# MKE16F16 register map
Vendor: Freescale Semiconductor, Inc.; Series: Kinetis_E; File version: 1.6
CPU: CM4 r0p1, little endian, no MPU, FPU, VTOR, 4 interrupt priority bits
Registers are 32-bit, read-write, reset 0x0 unless marked. A register's access mark holds for its fields unless they carry their own. Offsets are from the block's base; [hi:lo] are bit positions; {n}, {i} and the like mark numbered series; 'fields as' and 'values as' point back to an identical list.

## MCM — Core Platform Miscellaneous Control Module
Base 0xE0080000; register names take the prefix MCM_
0x08 PLASC 16-bit ro reset 0x7 — Crossbar Switch (AXBS) Slave Configuration
  [7:0] ASC — Each bit in the ASC field indicates whether there is a corresponding connection to the crossbar switch's slave input port.
    0=A bus slave connection to AXBS input port n is absent; 1=A bus slave connection to AXBS input port n is present
0x0A PLAMC 16-bit ro reset 0x7 — Crossbar Switch (AXBS) Master Configuration
  [7:0] AMC — Each bit in the AMC field indicates whether there is a corresponding connection to the AXBS master input port.
    0=A bus master connection to AXBS input port n is absent; 1=A bus master connection to AXBS input port n is present
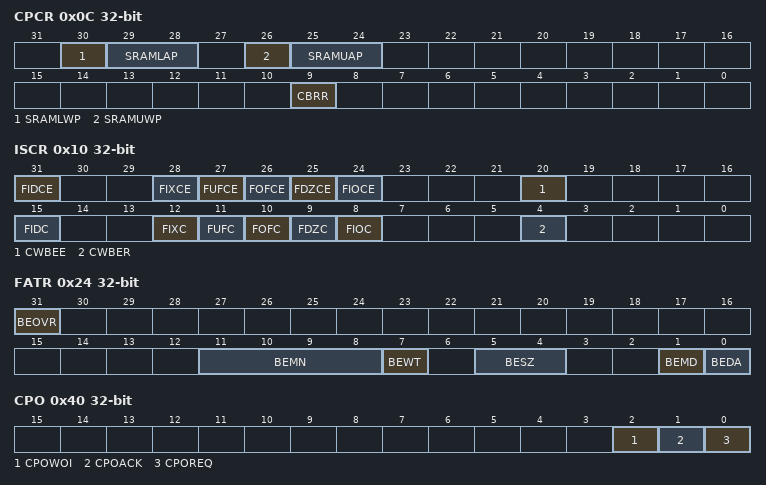
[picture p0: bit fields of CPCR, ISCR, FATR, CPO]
0x0C CPCR — Core Platform Control Register
  [30] SRAMLWP — SRAM_L Write Protect
  [29:28] SRAMLAP — SRAM_L arbitration priority
    0=Round robin; 1=Special round robin (favors SRAM backdoor accesses over the processor); 2=Fixed priority. Processor has highest, backdoor has lowest; 3=Fixed priority. Backdoor has highest, processor has lowest
  [26] SRAMUWP — SRAM_U write protect
  [25:24] SRAMUAP — SRAM_U arbitration priority
    values as SRAMLAP
  [9] CBRR — Crossbar round-robin arbitration enable
    0=Fixed-priority arbitration; 1=Round-robin arbitration
0x10 ISCR — Interrupt Status and Control Register
  [31] FIDCE — FPU input denormal interrupt enable
    0=Disable interrupt; 1=Enable interrupt
  [28] FIXCE — FPU inexact interrupt enable
    0=Disable interrupt; 1=Enable interrupt
  [27] FUFCE — FPU underflow interrupt enable
    0=Disable interrupt; 1=Enable interrupt
  [26] FOFCE — FPU overflow interrupt enable
    0=Disable interrupt; 1=Enable interrupt
  [25] FDZCE — FPU divide-by-zero interrupt enable
    0=Disable interrupt; 1=Enable interrupt
  [24] FIOCE — FPU invalid operation interrupt enable
    0=Disable interrupt; 1=Enable interrupt
  [20] CWBEE — Cache write buffer error enable
    0=Disable error interrupt; 1=Enable error interrupt
  [15] FIDC ro — FPU input denormal interrupt status
    0=No interrupt; 1=Interrupt occurred
  [12] FIXC ro — FPU inexact interrupt status
    0=No interrupt; 1=Interrupt occurred
  [11] FUFC ro — FPU underflow interrupt status
    0=No interrupt; 1=Interrupt occurred
  [10] FOFC ro — FPU overflow interrupt status
    0=No interrupt; 1=Interrupt occurred
  [9] FDZC ro — FPU divide-by-zero interrupt status
    0=No interrupt; 1=Interrupt occurred
  [8] FIOC ro — FPU invalid operation interrupt status
    0=No interrupt; 1=Interrupt occurred
  [4] CWBER — Cache write buffer error status
    0=No error; 1=Error occurred
0x20 FADR ro reset not defined — Store Buffer Fault address register
  [31:0] ADDRESS — Fault address
0x24 FATR ro reset not defined — Store Buffer Fault Attributes register
  [31] BEOVR — Bus error overrun
    0=No bus error overrun; 1=Bus error overrun occurred. The FADR and FDR registers and the other FATR bits are not updated to reflect this new bus error.
  [11:8] BEMN — Bus error master number
  [7] BEWT — Bus error write
    0=Read access; 1=Write access
  [5:4] BESZ — Bus error size
    0=8-bit access; 1=16-bit access; 2=32-bit access
  [1] BEMD — Bus error privilege level
    0=User mode; 1=Supervisor/privileged mode
  [0] BEDA — Bus Error Data Access type
    0=Instruction; 1=Data
0x28 FDR ro reset not defined — Store Buffer Fault Data Register
  [31:0] DATA — Fault data
0x30 PID — Process ID register
  [7:0] PID — M0_PID And M1_PID For MPU
0x40 CPO — Compute Operation Control Register
  [2] CPOWOI — Compute Operation wakeup on interrupt
    0=No effect; 1=When set, the CPOREQ is cleared on any interrupt or exception vector fetch
  [1] CPOACK ro — Compute Operation acknowledge
    0=Compute operation entry has not completed or compute operation exit has completed; 1=Compute operation entry has completed or compute operation exit has not completed
  [0] CPOREQ — Compute Operation request
    0=Request is cleared; 1=Request Compute Operation
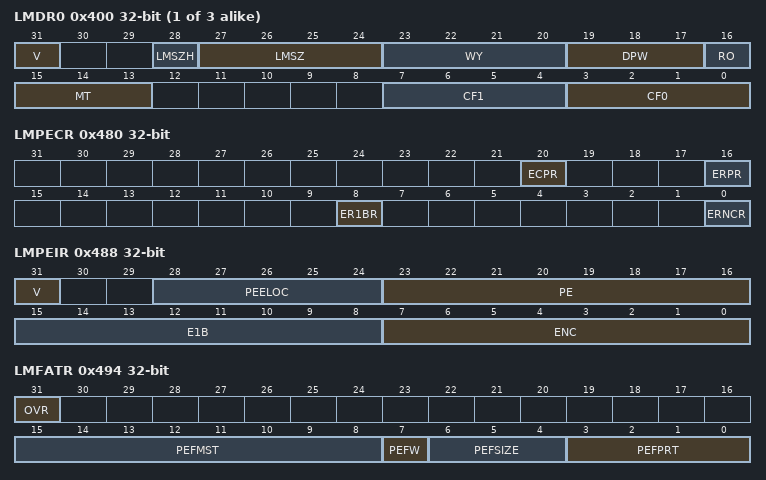
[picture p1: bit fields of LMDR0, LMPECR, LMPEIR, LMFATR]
{0x400+4i} LMDR{i} (i=0..2) reset not defined — Local Memory Descriptor Register
  [31] V ro — Local memory Valid bit. This read-only field defines the validity (presence) of the local memory.
    0=(??TBD?? current content from "MSCM OCMEM Configuration Register Descriptions"). LMEMn is not present.; 1=(??TBD?? current content from "MSCM OCMEM Configuration Register Descriptions"). LMEMn is present.
  [28] LMSZH ro — (??TBD?? current content from "MSCM OCMEM Configuration Register Descriptions")
    0=LMEMn is a power-of-2 capacity; 1=LMEMn is not a power-of-2, with a capacity is 0.75 * LMSZ
  [27:24] LMSZ ro — (??TBD?? current content from "MSCM OCMEM Configuration Register Descriptions")
    0=no LMEMn (0 KB); 1=1 KB LMEMn; 2=2 KB LMEMn; 3=4 KB LMEMn; 4=8 KB LMEMn; 5=16 KB LMEMn; 6=32 KB LMEMn; 7=64 KB LMEMn; 8=128 KB LMEMn; 9=256 KB LMEMn; 10=512 KB LMEMn; 11=1024 KB LMEMn; 12=2048 KB LMEMn; 13=4096 KB LMEMn; 14=8192 KB LMEMn; 15=16384 KB LMEMn
  [23:20] WY ro — Level 1 Cache Ways
    0=No Cache; 2=2-Way Set Associative; 4=4-Way Set Associative
  [19:17] DPW ro — LMEM Data Path Width. This read-only field defines the width of the local memory.
    2=LMEMn 32-bits wide; 3=LMEMn 64-bits wide
  [16] RO ro — (??TBD?? current content from "MSCM OCMEM Configuration Register Descriptions")
    0=(??TBD?? current content from "MSCM OCMEM Configuration Register Descriptions"). Writes to the LMDRn[7:0] are allowed.; 1=(??TBD?? current content from "MSCM OCMEM Configuration Register Descriptions"). Writes to the LMDRn[7:0] are ignored.
  [15:13] MT ro — Memory Type
    0=SRAM_L; 1=SRAM_U; 2=PC Cache; 3=PS Cache
  [7:4] CF1 — Control Field 1 - for Cache Parity control functions
  [3:0] CF0 — Control Field 0
0x480 LMPECR — LMEM Parity & ECC Control Register
  [all] fields
    0=reporting enabled; 1=reporting disabled
  [20] ECPR — Enable Cache Parity Reporting
  [16] ERPR — Enable RAM Parity Reporting
  [8] ER1BR — Enable RAM ECC 1 Bit Reporting
  [0] ERNCR — Enable RAM ECC Noncorrectable Reporting
0x488 LMPEIR — LMEM Parity & ECC Interrupt Register
  [31] V ro — Valid bit
  [28:24] PEELOC — Parity or ECC Error Location 5'h00 - a non-correctable ECC event from SRAM_L 5'h01 - a non-correctable ECC event from SRAM_U 5'h08 - a 1-bit correctable ECC event from SRAM_L 5'h09 - a 1-bit correctable ECC event from SRAM_U 5'h14 - a PC Tag Parity Error 5'h15 - a PC Data Parity Error
  [23:16] PE — Parity Error
  [15:8] E1B — E1Bn = ECC 1-bit Error n
  [7:0] ENC — ENCn = ECC Noncorrectable Error n
0x490 LMFAR ro — LMEM Fault Address Register
  [31:0] EFADD — ECC Fault Address
0x494 LMFATR — LMEM Fault Attribute Register
  [31] OVR ro — Overrun
  [15:8] PEFMST ro — Parity/ECC Fault Master Number
  [7] PEFW ro — Parity/ECC Fault Write
  [6:4] PEFSIZE — Parity/ECC Fault Master Size 3'b000 = 8-bit access 3'b001 = 16-bit access 3'b010 = 32-bit access 3'b011 = 64-bit access 3'b1xx = Reserved
  [3:0] PEFPRT — Parity/ECC Fault Protection FATR[3] is Cacheable: 0=Non-cacheable, 1=Cacheable FATR[2] is Bufferable: 0=Non-bufferable, 1=Bufferable FATR[1] is Mode: 0=User mode, 1=Supervisor mode FATR[0] is Type: 0=I-Fetch, 1=Data
0x4A0 LMFDHR ro — LMEM Fault Data High Register
  [31:0] PEFDH — Parity or ECC Fault Data High
0x4A4 LMFDLR ro — LMEM Fault Data Low Register
  [31:0] PEFDL — Parity or ECC Fault Data Low
